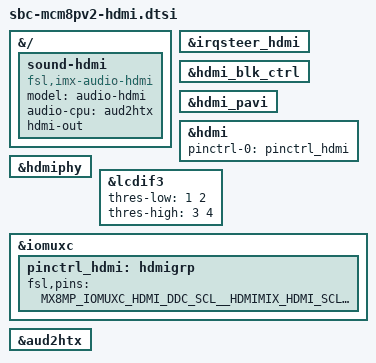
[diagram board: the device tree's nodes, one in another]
// SPDX-License-Identifier: (GPL-2.0+ OR MIT)
/* Copyright 2026 CompuLab Ltd. */

/* Native HDMI output at P22: power and level shifting are fixed on sheet 8. */
&{/} {
	sound-hdmi {
		compatible = "fsl,imx-audio-hdmi";
		model = "audio-hdmi";
		audio-cpu = <&aud2htx>;
		hdmi-out;
		status = "okay";
	};
};

&irqsteer_hdmi {
	status = "okay";
};

&hdmi_blk_ctrl {
	status = "okay";
};

&hdmi_pavi {
	status = "okay";
};

&hdmi {
	pinctrl-names = "default";
	pinctrl-0 = <&pinctrl_hdmi>;
	status = "okay";
};

&hdmiphy {
	status = "okay";
};

&lcdif3 {
	status = "okay";

	thres-low = <1 2>; /* (FIFO * 1 / 2) */
	thres-high = <3 4>; /* (FIFO * 3 / 4) */
};

&iomuxc {
	pinctrl_hdmi: hdmigrp {
		fsl,pins = <
			MX8MP_IOMUXC_HDMI_DDC_SCL__HDMIMIX_HDMI_SCL	0x400001c3
			MX8MP_IOMUXC_HDMI_DDC_SDA__HDMIMIX_HDMI_SDA	0x400001c3
			MX8MP_IOMUXC_HDMI_HPD__HDMIMIX_HDMI_HPD		0x40000019
			MX8MP_IOMUXC_HDMI_CEC__HDMIMIX_HDMI_CEC		0x40000019
		>;
	};
};

&aud2htx {
	status = "okay";
};
